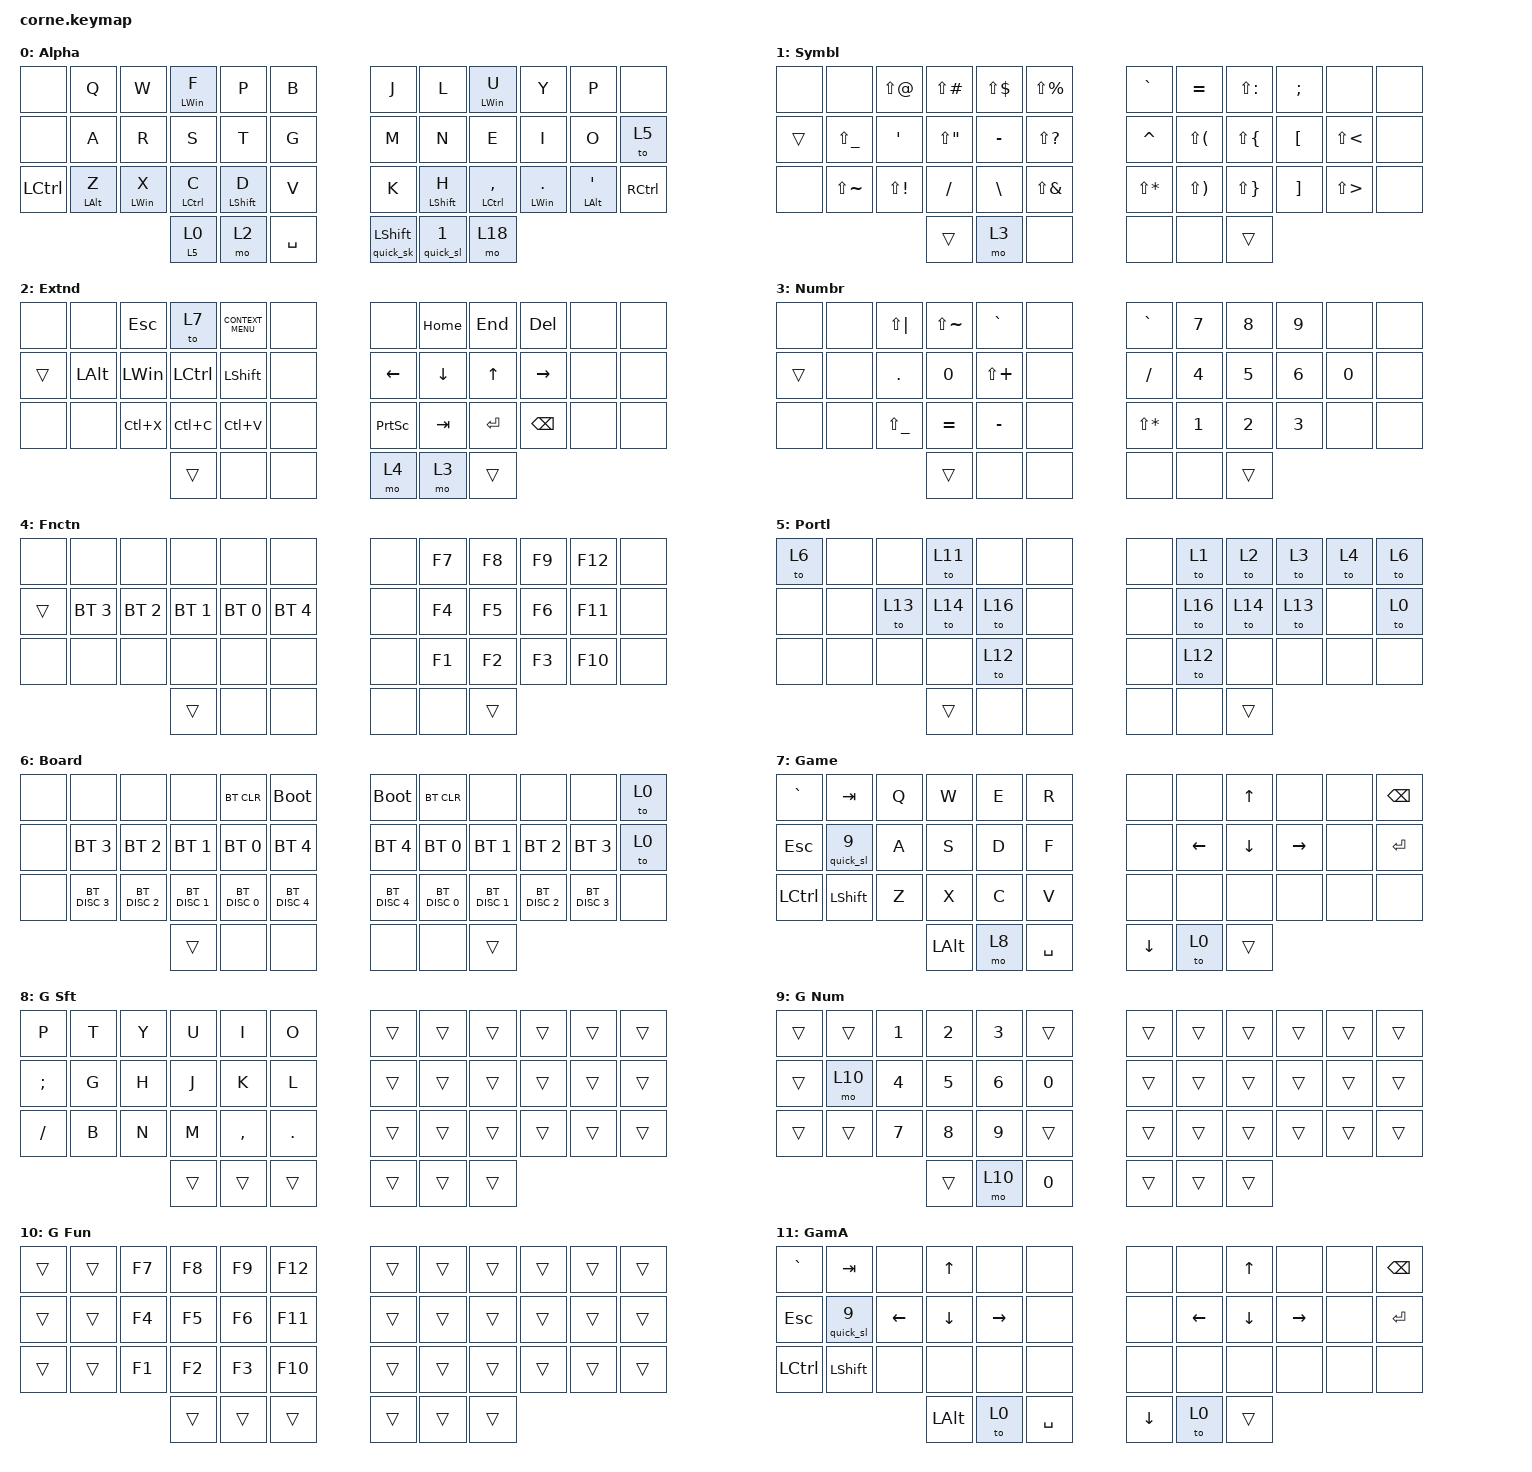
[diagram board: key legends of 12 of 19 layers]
/*
 * Copyright (c) 2020 The ZMK Contributors
 *
 * SPDX-License-Identifier: MIT
 */

#include <behaviors.dtsi>
#include <dt-bindings/zmk/bt.h>
#include <dt-bindings/zmk/keys.h>

/ {
    behaviors {
        left_alpha_mod: left_alpha_mod {
            compatible = "zmk,behavior-hold-tap";
            label = "LEFT_ALPHA_MOD";
            bindings = <&kp>, <&kp>;

            #binding-cells = <2>;
            tapping-term-ms = <200>;
            flavor = "tap-preferred";
            hold-trigger-key-positions = <6 30 18 31 19 7 9 8 9 10 11 20 21 22 23 32 33 34 35 41 39 40>;
        };

        right_alpha_mod: right_alpha_mod {
            compatible = "zmk,behavior-hold-tap";
            label = "RIGHT_ALPHA_MOD";
            bindings = <&kp>, <&kp>;

            #binding-cells = <2>;
            tapping-term-ms = <200>;
            flavor = "tap-preferred";
            hold-trigger-key-positions = <0 1 2 4 5 12 13 14 15 16 17 24 25 26 27 28 29 36 37 38 3>;
        };

        alpha_mod: alpha_mod {
            compatible = "zmk,behavior-hold-tap";
            label = "ALPHA_MOD";
            bindings = <&kp>, <&kp>;

            #binding-cells = <2>;
            tapping-term-ms = <200>;
            flavor = "tap-preferred";
        };

        quick_sl: quick_sl {
            compatible = "zmk,behavior-sticky-key";
            label = "QUICK_SL";
            bindings = <&mo>;
            #binding-cells = <1>;
            quick-release;
            release-after-ms = <200>;
        };

        quick_sk: quick_sk {
            compatible = "zmk,behavior-sticky-key";
            label = "QUICK_SK";
            bindings = <&kp>;
            #binding-cells = <1>;
            quick-release;
            ignore-modifiers;
            release-after-ms = <200>;
        };

        portal_switch: portal_switch {
            compatible = "zmk,behavior-hold-tap";
            label = "PORTAL_SWITCH";
            bindings = <&mo>, <&to>;

            #binding-cells = <2>;
            tapping-term-ms = <150>;
        };
    };

    combos {
        compatible = "zmk,combos";

        anki_enter {
            bindings = <&kp ENTER>;
            key-positions = <7 19>;
            layers = <13>;
        };

        anki_more {
            bindings = <&anki_more>;
            key-positions = <6 18>;
            layers = <13>;
        };

        anki_esc {
            bindings = <&kp ESCAPE>;
            key-positions = <18 30>;
            layers = <13>;
        };

        star_symbol {
            bindings = <&kp ASTERISK>;
            key-positions = <15 16>;
            layers = <1>;
        };

        grave_symbol {
            bindings = <&kp GRAVE>;
            key-positions = <2 3>;
            layers = <1>;
        };

        save {
            bindings = <&kp LC(S)>;
            key-positions = <14 15>;
            layers = <14 16>;
        };
    };

    macros {
        anki_more: anki_more {
            compatible = "zmk,behavior-macro";
            #binding-cells = <0>;
            bindings = <&kp LEFT_ALT &kp M>;
            label = "ANKI_MORE";
        };

        krita_pan: krita_pan {
            compatible = "zmk,behavior-macro";
            #binding-cells = <0>;
            bindings = <&mo 0>;
            label = "KRITA_PAN";
        };
    };

    keymap {
        compatible = "zmk,keymap";

        Normal {
            // -----------------------------------------------------------------------------------------
            // |  TAB |  Q  |  W  |  E  |  R  |  T  |   |  Y  |  U   |  I  |  O  |  P  | BSPC |
            // | CTRL |  A  |  S  |  D  |  F  |  G  |   |  H  |  J   |  K  |  L  |  ;  |  '   |
            // | SHFT |  Z  |  X  |  C  |  V  |  B  |   |  N  |  M   |  ,  |  .  |  /  | ESC  |
            //                    | GUI | LWR | SPC |   | ENT | RSE  | ALT |

            bindings = <
&none             &kp Q                  &kp W                  &alpha_mod LEFT_WIN F      &kp P                    &kp B        &kp J                 &kp L                    &alpha_mod LEFT_WIN U          &kp Y                    &kp P                    &none
&none             &kp A                  &kp R                  &kp S                      &kp T                    &kp G        &kp M                 &kp N                    &kp E                          &kp I                    &kp O                    &to 5
&kp LEFT_CONTROL  &alpha_mod LEFT_ALT Z  &alpha_mod LEFT_WIN X  &alpha_mod LEFT_CONTROL C  &alpha_mod LEFT_SHIFT D  &kp V        &kp K                 &alpha_mod LEFT_SHIFT H  &alpha_mod LEFT_CONTROL COMMA  &alpha_mod LEFT_WIN DOT  &alpha_mod LEFT_ALT SQT  &kp RCTRL
                                                                &portal_switch 5 0         &mo 2                    &kp SPACE    &quick_sk LEFT_SHIFT  &quick_sl 1              &mo 18
            >;

            label = "Alpha";
        };

        Symbols {
            bindings = <
&none   &none          &kp LS(AT)    &kp LS(POUND)  &kp LS(DLLR)  &kp LS(PRCNT)       &kp GRAVE     &kp EQUAL     &kp LS(COLON)  &kp SEMI  &none       &none
&trans  &kp LS(UNDER)  &kp SQT       &kp LS(DQT)    &kp MINUS     &kp LS(QUESTION)    &kp CARET     &kp LS(LPAR)  &kp LS(LBRC)   &kp LBKT  &kp LS(LT)  &none
&none   &kp LS(TILDE)  &kp LS(EXCL)  &kp FSLH       &kp BSLH      &kp LS(AMPS)        &kp LS(STAR)  &kp LS(RPAR)  &kp LS(RBRC)   &kp RBKT  &kp LS(GT)  &none
                                     &trans         &mo 3         &none               &none         &none         &trans
            >;

            label = "Symbl";
        };

        Extend {
            bindings = <
&none   &none         &kp ESC       &to 7      &kp K_CONTEXT_MENU  &none    &none            &kp HOME  &kp END  &kp DEL    &none  &none
&trans  &kp LEFT_ALT  &kp LEFT_WIN  &kp LCTRL  &kp LSHFT           &none    &kp LEFT         &kp DOWN  &kp UP   &kp RIGHT  &none  &none
&none   &none         &kp LC(X)     &kp LC(C)  &kp LC(V)           &none    &kp PRINTSCREEN  &kp TAB   &kp RET  &kp BSPC   &none  &none
                                    &trans     &none               &none    &mo 4            &mo 3     &trans
            >;

            label = "Extnd";
        };

        Numbers {
            bindings = <
&none   &none  &kp LS(PIPE)   &kp LS(TILDE)  &kp GRAVE     &none    &kp GRAVE     &kp N7  &kp N8  &kp N9  &none   &none
&trans  &none  &kp DOT        &kp N0         &kp LS(PLUS)  &none    &kp FSLH      &kp N4  &kp N5  &kp N6  &kp N0  &none
&none   &none  &kp LS(UNDER)  &kp EQUAL      &kp MINUS     &none    &kp LS(STAR)  &kp N1  &kp N2  &kp N3  &none   &none
                              &trans         &none         &none    &none         &none   &trans
            >;

            label = "Numbr";
        };

        Function {
            bindings = <
&none   &none         &none         &none         &none         &none           &none  &kp F7  &kp F8  &kp F9  &kp F12  &none
&trans  &bt BT_SEL 3  &bt BT_SEL 2  &bt BT_SEL 1  &bt BT_SEL 0  &bt BT_SEL 4    &none  &kp F4  &kp F5  &kp F6  &kp F11  &none
&none   &none         &none         &none         &none         &none           &none  &kp F1  &kp F2  &kp F3  &kp F10  &none
                                    &trans        &none         &none           &none  &none   &trans
            >;

            label = "Fnctn";
        };

        Portal {
            bindings = <
&to 6  &none  &none   &to 11  &none   &none    &none  &to 1   &to 2   &to 3   &to 4  &to 6
&none  &none  &to 13  &to 14  &to 16  &none    &none  &to 16  &to 14  &to 13  &none  &to 0
&none  &none  &none   &none   &to 12  &none    &none  &to 12  &none   &none   &none  &none
                      &trans  &none   &none    &none  &none   &trans
            >;

            label = "Portl";
        };

        Board {
            bindings = <
&none  &none          &none          &none          &bt BT_CLR     &bootloader      &bootloader    &bt BT_CLR     &none          &none          &none          &to 0
&none  &bt BT_SEL 3   &bt BT_SEL 2   &bt BT_SEL 1   &bt BT_SEL 0   &bt BT_SEL 4     &bt BT_SEL 4   &bt BT_SEL 0   &bt BT_SEL 1   &bt BT_SEL 2   &bt BT_SEL 3   &to 0
&none  &bt BT_DISC 3  &bt BT_DISC 2  &bt BT_DISC 1  &bt BT_DISC 0  &bt BT_DISC 4    &bt BT_DISC 4  &bt BT_DISC 0  &bt BT_DISC 1  &bt BT_DISC 2  &bt BT_DISC 3  &none
                                     &trans         &none          &none            &none          &none          &trans
            >;

            label = "Board";
        };

        Game {
            bindings = <
&kp GRAVE  &kp TAB      &kp Q  &kp W         &kp E  &kp R        &none     &none     &kp UP_ARROW  &none      &none  &kp BSPC
&kp ESC    &quick_sl 9  &kp A  &kp S         &kp D  &kp F        &none     &kp LEFT  &kp DOWN      &kp RIGHT  &none  &kp ENTER
&kp LCTRL  &kp LSHFT    &kp Z  &kp X         &kp C  &kp V        &none     &none     &none         &none      &none  &none
                               &kp LEFT_ALT  &mo 8  &kp SPACE    &kp DOWN  &to 0     &trans
            >;

            label = "Game";
        };

        GameShift {
            bindings = <
&kp P     &kp T  &kp Y  &kp U   &kp I      &kp O      &trans  &trans  &trans  &trans  &trans  &trans
&kp SEMI  &kp G  &kp H  &kp J   &kp K      &kp L      &trans  &trans  &trans  &trans  &trans  &trans
&kp FSLH  &kp B  &kp N  &kp M   &kp COMMA  &kp DOT    &trans  &trans  &trans  &trans  &trans  &trans
                        &trans  &trans     &trans     &trans  &trans  &trans
            >;

            label = "G Sft";
        };

        GameNumber {
            bindings = <
&trans  &trans  &kp N1  &kp N2  &kp N3  &trans    &trans  &trans  &trans  &trans  &trans  &trans
&trans  &mo 10  &kp N4  &kp N5  &kp N6  &kp N0    &trans  &trans  &trans  &trans  &trans  &trans
&trans  &trans  &kp N7  &kp N8  &kp N9  &trans    &trans  &trans  &trans  &trans  &trans  &trans
                        &trans  &mo 10  &kp N0    &trans  &trans  &trans
            >;

            label = "G Num";
        };

        GameFunction {
            bindings = <
&trans  &trans  &kp F7  &kp F8  &kp F9  &kp F12    &trans  &trans  &trans  &trans  &trans  &trans
&trans  &trans  &kp F4  &kp F5  &kp F6  &kp F11    &trans  &trans  &trans  &trans  &trans  &trans
&trans  &trans  &kp F1  &kp F2  &kp F3  &kp F10    &trans  &trans  &trans  &trans  &trans  &trans
                        &trans  &trans  &trans     &trans  &trans  &trans
            >;

            label = "G Fun";
        };

        GameArrows {
            label = "GamA";
            bindings = <
&kp GRAVE  &kp TAB      &none     &kp UP        &none      &none        &none     &none     &kp UP_ARROW  &none      &none  &kp BSPC
&kp ESC    &quick_sl 9  &kp LEFT  &kp DOWN      &kp RIGHT  &none        &none     &kp LEFT  &kp DOWN      &kp RIGHT  &none  &kp ENTER
&kp LCTRL  &kp LSHFT    &none     &none         &none      &none        &none     &none     &none         &none      &none  &none
                                  &kp LEFT_ALT  &to 0      &kp SPACE    &kp DOWN  &to 0     &trans
            >;
        };

        Video {
            bindings = <
&none  &kp ENTER  &kp UP_ARROW  &kp J      &kp L       &none        &none  &kp SPACE  &kp RIGHT  &kp L     &kp DOT    &none
&none  &kp C      &kp DOWN      &kp LEFT   &kp RIGHT   &none        &none  &kp RET    &kp LEFT   &kp J     &kp COMMA  &to 0
&none  &none      &kp I         &kp COMMA  &kp PERIOD  &none        &none  &kp C      &kp UP     &kp DOWN  &none      &none
                                &trans     &none       &kp SPACE    &to 0  &none      &trans
            >;

            label = "Video";
        };

        Anki {
            bindings = <
&none  &none  &none  &none   &none  &none    &kp UP_ARROW  &kp N3     &kp N4         &kp LC(NUMBER_1)  &none  &none
&none  &none  &none  &none   &none  &none    &kp DOWN      &kp N1     &kp N2         &kp MINUS         &none  &to 0
&none  &none  &none  &none   &none  &none    &kp SLASH     &kp LC(Z)  &kp LS(LC(Z))  &kp AT_SIGN       &none  &none
                     &trans  &none  &none    &kp Y         &none      &trans
            >;

            label = "Anki";
        };

        Krita {
            bindings = <
&none  &kp LC(EQUAL)  &kp LC(R)  &kp LCTRL          &kp T           &kp F            &none     &none     &none   &none      &none  &none
&none  &kp B          &kp R      &kp LC(Z)          &kp E           &kp LC(LS(Z))    &kp LEFT  &kp DOWN  &kp UP  &kp RIGHT  &none  &none
&none  &kp LC(MINUS)  &none      &kp LC(LA(SPACE))  &kp LEFT_SHIFT  &none            &none     &none     &none   &none      &none  &none
                                 &trans             &mo 15          &kp SPACE        &none     &to 0     &trans
            >;

            label = "Krita";
        };

        KritaAlt {
            bindings = <
&none  &none  &kp LC(LS(A))  &kp LC(LS(LA(J)))  &kp DEL    &kp LS(DEL)    &none  &none  &none   &none  &none  &none
&none  &none  &kp LC(G)      &kp INS            &kp LC(J)  &none          &none  &none  &none   &none  &none  &none
&none  &none  &kp LC(X)      &kp LC(C)          &kp LC(V)  &none          &none  &none  &none   &none  &none  &none
                             &trans             &none      &none          &none  &none  &trans
            >;

            label = "K Alt";
        };

        Pdn {
            bindings = <
&none  &none  &kp P  &kp S      &kp M      &kp F        &none     &none     &none   &none      &none  &none
&none  &none  &kp B  &kp LC(Z)  &kp K      &kp LC(Y)    &kp LEFT  &kp DOWN  &kp UP  &kp RIGHT  &none  &none
&none  &none  &kp X  &kp C      &kp LC(S)  &none        &none     &none     &none   &none      &none  &none
                     &trans     &mo 17     &kp SPACE    &none     &to 0     &trans
            >;

            label = "PDN";
        };

        PdnAlt {
            bindings = <
&none  &none  &kp ESC    &kp BSPC   &kp DEL    &none    &none  &none  &none   &none  &none  &none
&none  &none  &kp LALT   &kp LCTRL  &kp LSHFT  &none    &none  &none  &none   &none  &none  &none
&none  &none  &kp LC(X)  &kp LC(C)  &kp LC(V)  &none    &none  &none  &none   &none  &none  &none
                         &trans     &none      &none    &none  &none  &trans
            >;

            label = "P Alt";
        };

        Global {
            bindings = <
&none  &none  &none  &none   &none  &none    &none  &kp LG(L)   &kp C_BRIGHTNESS_DEC  &kp C_BRIGHTNESS_INC  &kp LS(LG(LA(B)))  &none
&none  &none  &none  &none   &none  &none    &none  &kp C_PREV  &kp C_PLAY_PAUSE      &kp C_NEXT            &kp LA(LS(LG(P)))  &none
&none  &none  &none  &none   &none  &none    &none  &kp C_MUTE  &kp C_VOLUME_DOWN     &kp C_VOLUME_UP       &kp LS(LG(LA(Q)))  &none
                     &trans  &none  &none    &none  &none       &trans
            >;

            label = "Globl";
        };
    };
};
